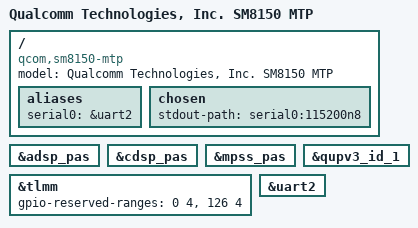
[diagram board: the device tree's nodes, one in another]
// SPDX-License-Identifier: GPL-2.0
// Copyright (c) 2019, Linaro Limited

/dts-v1/;

#include "sm8150.dtsi"

/ {
	model = "Qualcomm Technologies, Inc. SM8150 MTP";
	compatible = "qcom,sm8150-mtp";

	aliases {
		serial0 = &uart2;
	};

	chosen {
		stdout-path = "serial0:115200n8";
	};
};

&adsp_pas {
	status = "okay";
};

&cdsp_pas {
	status = "okay";
};

&mpss_pas {
	status = "okay";
};

&qupv3_id_1 {
	status = "okay";
};

&tlmm {
	gpio-reserved-ranges = <0 4>, <126 4>;
};

&uart2 {
	status = "okay";
};
